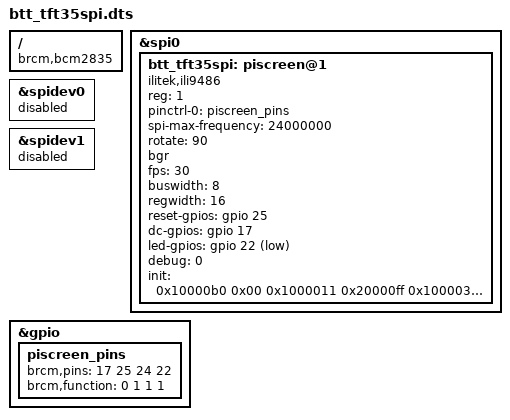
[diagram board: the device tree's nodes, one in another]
/*
 * Device Tree overlay for PiScreen 3.5" display shield by Ozzmaker
 *
 */

/dts-v1/;
/plugin/;

/ {
	compatible = "brcm,bcm2835", "brcm,bcm2708", "brcm,bcm2709";

	fragment@0 {
		target = <&spi0>;
		__overlay__ {
			status = "okay";
		};
	};

	fragment@1 {
		target = <&spidev0>;
		__overlay__ {
			status = "disabled";
		};
	};

	fragment@2 {
		target = <&spidev1>;
		__overlay__ {
			status = "disabled";
		};
	};

	fragment@3 {
		target = <&gpio>;
		__overlay__ {
			piscreen_pins: piscreen_pins {
				brcm,pins = <17 25 24 22>;
				brcm,function = <0 1 1 1>; /* in out out out */
			};
		};
	};

	fragment@4 {
		target = <&spi0>;
		__overlay__ {
			/* needed to avoid dtc warning */
			#address-cells = <1>;
			#size-cells = <0>;

			btt_tft35spi: piscreen@1{
				compatible = "ilitek,ili9486";
				reg = <1>;
				pinctrl-names = "default";
				pinctrl-0 = <&piscreen_pins>;

				spi-max-frequency = <24000000>;
				rotate = <90>;
				bgr;
				fps = <30>;
				buswidth = <8>;
				regwidth = <16>;
				reset-gpios = <&gpio 25 0>;
				dc-gpios = <&gpio 17 0>;
				led-gpios = <&gpio 22 1>;
				debug = <0>;

				init = <0x10000b0 0x00
				        0x1000011
					0x20000ff
					0x100003a 0x55
					0x1000036 0x28
					0x10000c2 0x44
					0x10000c5 0x00 0x00 0x00 0x00
					0x10000e0 0x0f 0x1f 0x1c 0x0c 0x0f 0x08 0x48 0x98 0x37 0x0a 0x13 0x04 0x11 0x0d 0x00
					0x10000e1 0x0f 0x32 0x2e 0x0b 0x0d 0x05 0x47 0x75 0x37 0x06 0x10 0x03 0x24 0x20 0x00
					0x10000e2 0x0f 0x32 0x2e 0x0b 0x0d 0x05 0x47 0x75 0x37 0x06 0x10 0x03 0x24 0x20 0x00
					0x1000011
					0x1000029>;
			};
		};
	};
	__overrides__ {
		speed =		<&btt_tft35spi>,"spi-max-frequency:0";
		rotate =	<&btt_tft35spi>,"rotate:0";
		fps =		<&btt_tft35spi>,"fps:0";
		debug =		<&btt_tft35spi>,"debug:0";
	};
};

